# jbr_MDR1986VE3 register map
Registers are 32-bit, access not given, no defined reset value unless marked. A register's access mark holds for its fields unless they carry their own. Addresses are absolute; registers are grouped by the start of their names; [hi:lo] are bit positions; {n}, {i} and the like mark numbered series; 'fields as' and 'values as' point back to an identical list.

## ETH1
0x30000000 ETH1_Dilimiter 16-bit
0x30000002 ETH1_MAC_T 16-bit
0x30000004 ETH1_MAC_M 16-bit
0x30000006 ETH1_MAC_H 16-bit
{0x30000008+2i} ETH1_HASH{i} 16-bit (i=0..3)
0x30000010 ETH1_IPG 16-bit
0x30000012 ETH1_PSC 16-bit
0x30000014 ETH1_BAG 16-bit
0x30000016 ETH1_JitterWnd 16-bit
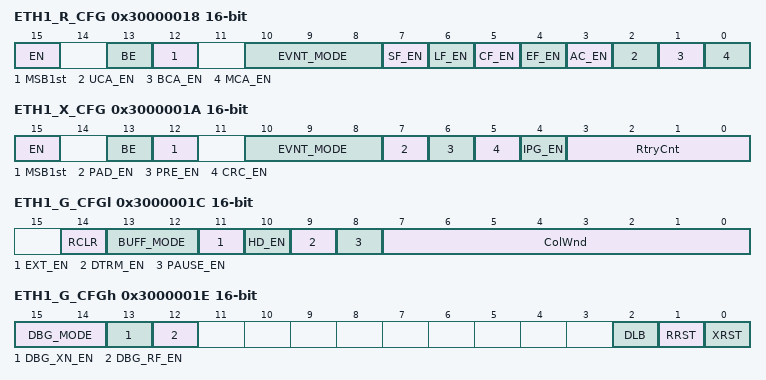
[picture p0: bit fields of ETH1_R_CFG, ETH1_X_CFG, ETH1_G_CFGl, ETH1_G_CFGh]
0x30000018 ETH1_R_CFG 16-bit
  [15] EN, [13] BE, [12] MSB1st, [10:8] EVNT_MODE, [7] SF_EN, [6] LF_EN, [5] CF_EN, [4] EF_EN, [3] AC_EN, [2] UCA_EN, [1] BCA_EN, [0] MCA_EN
0x3000001A ETH1_X_CFG 16-bit
  [15] EN, [13] BE, [12] MSB1st, [10:8] EVNT_MODE, [7] PAD_EN, [6] PRE_EN, [5] CRC_EN, [4] IPG_EN, [3:0] RtryCnt
0x3000001C ETH1_G_CFGl 16-bit
  [14] RCLR, [13:12] BUFF_MODE, [11] EXT_EN, [10] HD_EN, [9] DTRM_EN, [8] PAUSE_EN, [7:0] ColWnd
0x3000001E ETH1_G_CFGh 16-bit
  [15:14] DBG_MODE, [13] DBG_XN_EN, [12] DBG_RF_EN, [2] DLB, [1] RRST, [0] XRST
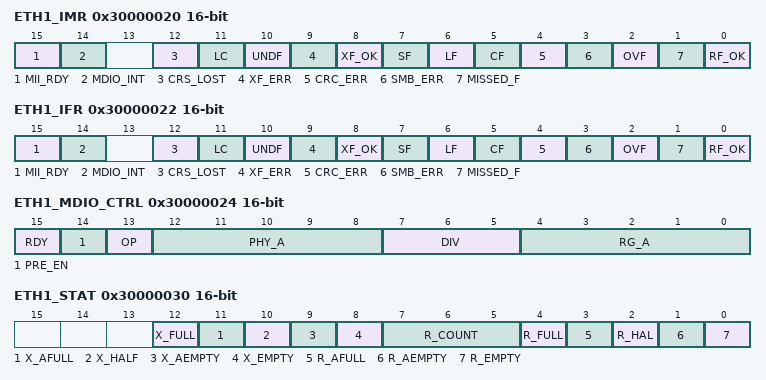
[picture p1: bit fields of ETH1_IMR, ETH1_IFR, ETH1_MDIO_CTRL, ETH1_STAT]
0x30000020 ETH1_IMR 16-bit
  [15] MII_RDY, [14] MDIO_INT, [12] CRS_LOST, [11] LC, [10] UNDF, [9] XF_ERR, [8] XF_OK, [7] SF, [6] LF, [5] CF, [4] CRC_ERR, [3] SMB_ERR, [2] OVF, [1] MISSED_F, [0] RF_OK
0x30000022 ETH1_IFR 16-bit
  fields as ETH1_IMR
0x30000024 ETH1_MDIO_CTRL 16-bit
  [15] RDY, [14] PRE_EN, [13] OP, [12:8] PHY_A, [7:5] DIV, [4:0] RG_A
0x30000026 ETH1_MDIO_DATA 16-bit
0x30000028 ETH1_R_Head 16-bit
0x3000002A ETH1_X_Tail 16-bit
0x3000002C ETH1_R_Tail 16-bit
0x3000002E ETH1_X_Head 16-bit
0x30000030 ETH1_STAT 16-bit
  [12] X_FULL, [11] X_AFULL, [10] X_HALF, [9] X_AEMPTY, [8] X_EMPTY, [7:5] R_COUNT, [4] R_FULL, [3] R_AFULL, [2] R_HAL, [1] R_AEMPTY, [0] R_EMPTY

## PHY1
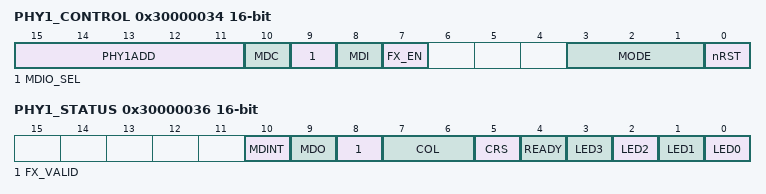
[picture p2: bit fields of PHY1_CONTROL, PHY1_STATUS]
0x30000034 PHY1_CONTROL 16-bit
  [15:11] PHY1ADD, [10] MDC, [9] MDIO_SEL, [8] MDI, [7] FX_EN, [3:1] MODE, [0] nRST
0x30000036 PHY1_STATUS 16-bit
  [10] MDINT, [9] MDO, [8] FX_VALID, [7:6] COL, [5] CRS, [4] READY, [n] LED{n} (n=0..3)

## ETH2
0x34000000 ETH2_Dilimiter 16-bit
0x34000002 ETH2_MAC_T 16-bit
0x34000004 ETH2_MAC_M 16-bit
0x34000006 ETH2_MAC_H 16-bit
{0x34000008+2i} ETH2_HASH{i} 16-bit (i=0..3)
0x34000010 ETH2_IPG 16-bit
0x34000012 ETH2_PSC 16-bit
0x34000014 ETH2_BAG 16-bit
0x34000016 ETH2_JitterWnd 16-bit
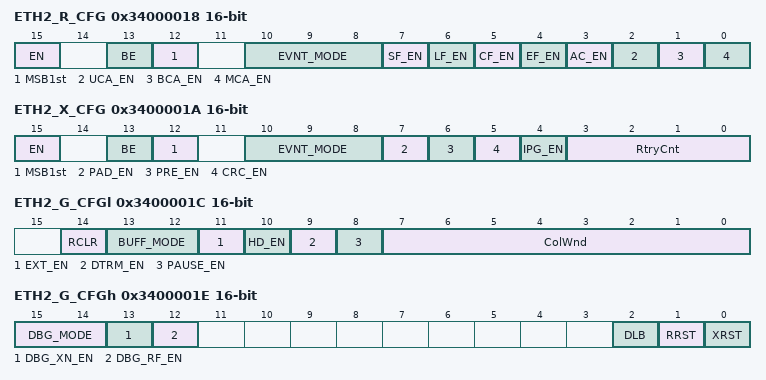
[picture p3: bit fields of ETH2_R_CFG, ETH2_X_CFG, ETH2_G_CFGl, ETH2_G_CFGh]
0x34000018 ETH2_R_CFG 16-bit
  [15] EN, [13] BE, [12] MSB1st, [10:8] EVNT_MODE, [7] SF_EN, [6] LF_EN, [5] CF_EN, [4] EF_EN, [3] AC_EN, [2] UCA_EN, [1] BCA_EN, [0] MCA_EN
0x3400001A ETH2_X_CFG 16-bit
  [15] EN, [13] BE, [12] MSB1st, [10:8] EVNT_MODE, [7] PAD_EN, [6] PRE_EN, [5] CRC_EN, [4] IPG_EN, [3:0] RtryCnt
0x3400001C ETH2_G_CFGl 16-bit
  [14] RCLR, [13:12] BUFF_MODE, [11] EXT_EN, [10] HD_EN, [9] DTRM_EN, [8] PAUSE_EN, [7:0] ColWnd
0x3400001E ETH2_G_CFGh 16-bit
  [15:14] DBG_MODE, [13] DBG_XN_EN, [12] DBG_RF_EN, [2] DLB, [1] RRST, [0] XRST
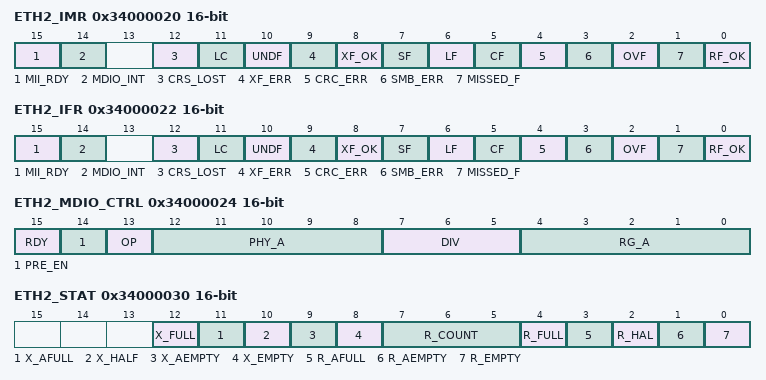
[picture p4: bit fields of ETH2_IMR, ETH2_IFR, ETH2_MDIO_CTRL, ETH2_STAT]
0x34000020 ETH2_IMR 16-bit
  [15] MII_RDY, [14] MDIO_INT, [12] CRS_LOST, [11] LC, [10] UNDF, [9] XF_ERR, [8] XF_OK, [7] SF, [6] LF, [5] CF, [4] CRC_ERR, [3] SMB_ERR, [2] OVF, [1] MISSED_F, [0] RF_OK
0x34000022 ETH2_IFR 16-bit
  fields as ETH2_IMR
0x34000024 ETH2_MDIO_CTRL 16-bit
  [15] RDY, [14] PRE_EN, [13] OP, [12:8] PHY_A, [7:5] DIV, [4:0] RG_A
0x34000026 ETH2_MDIO_DATA 16-bit
0x34000028 ETH2_R_Head 16-bit
0x3400002A ETH2_X_Tail 16-bit
0x3400002C ETH2_R_Tail 16-bit
0x3400002E ETH2_X_Head 16-bit
0x34000030 ETH2_STAT 16-bit
  [12] X_FULL, [11] X_AFULL, [10] X_HALF, [9] X_AEMPTY, [8] X_EMPTY, [7:5] R_COUNT, [4] R_FULL, [3] R_AFULL, [2] R_HAL, [1] R_AEMPTY, [0] R_EMPTY

## PHY2
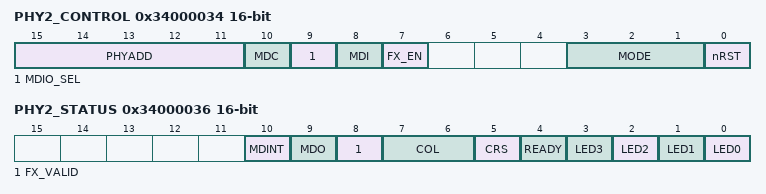
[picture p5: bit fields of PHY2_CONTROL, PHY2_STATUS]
0x34000034 PHY2_CONTROL 16-bit
  [15:11] PHYADD, [10] MDC, [9] MDIO_SEL, [8] MDI, [7] FX_EN, [3:1] MODE, [0] nRST
0x34000036 PHY2_STATUS 16-bit
  [10] MDINT, [9] MDO, [8] FX_VALID, [7:6] COL, [5] CRS, [4] READY, [n] LED{n} (n=0..3)

## SFR
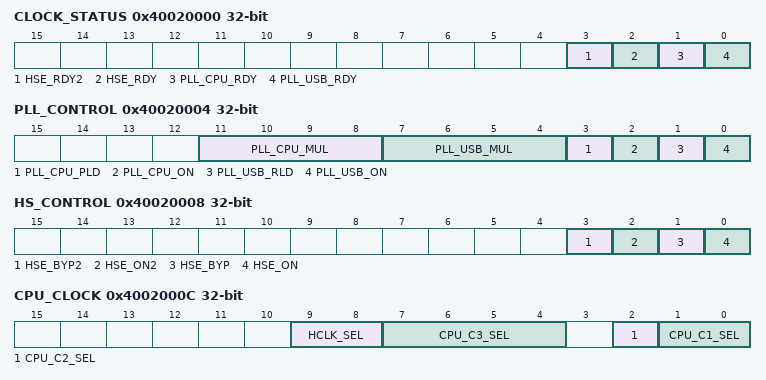
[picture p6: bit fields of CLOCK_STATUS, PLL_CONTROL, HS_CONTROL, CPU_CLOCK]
0x40020000 CLOCK_STATUS
  [3] HSE_RDY2, [2] HSE_RDY, [1] PLL_CPU_RDY, [0] PLL_USB_RDY
0x40020004 PLL_CONTROL
  [11:8] PLL_CPU_MUL, [7:4] PLL_USB_MUL, [3] PLL_CPU_PLD, [2] PLL_CPU_ON, [1] PLL_USB_RLD, [0] PLL_USB_ON
0x40020008 HS_CONTROL
  [3] HSE_BYP2, [2] HSE_ON2, [1] HSE_BYP, [0] HSE_ON
0x4002000C CPU_CLOCK
  [9:8] HCLK_SEL, [7:4] CPU_C3_SEL, [2] CPU_C2_SEL, [1:0] CPU_C1_SEL
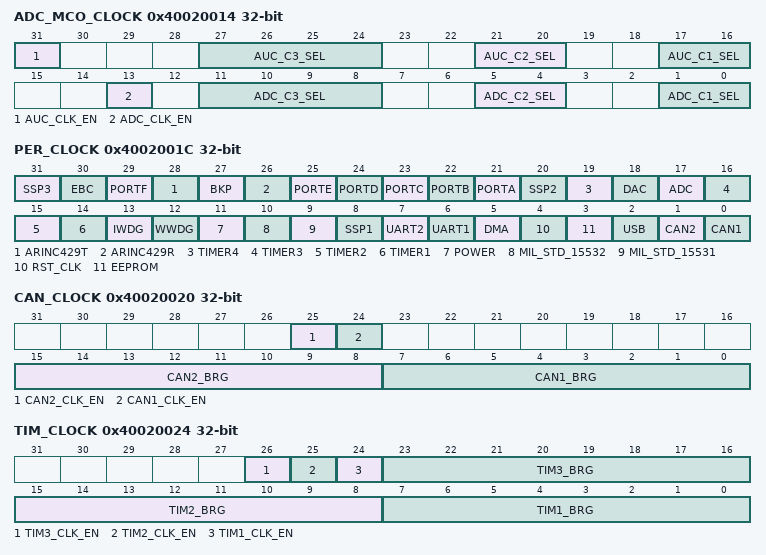
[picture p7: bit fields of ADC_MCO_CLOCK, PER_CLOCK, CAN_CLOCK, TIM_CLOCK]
0x40020014 ADC_MCO_CLOCK
  [31] AUC_CLK_EN, [27:24] AUC_C3_SEL, [21:20] AUC_C2_SEL, [17:16] AUC_C1_SEL, [13] ADC_CLK_EN, [11:8] ADC_C3_SEL, [5:4] ADC_C2_SEL, [1:0] ADC_C1_SEL
0x4002001C PER_CLOCK
  [31] SSP3, [30] EBC, [29] PORTF, [28] ARINC429T, [27] BKP, [26] ARINC429R, [25] PORTE, [24] PORTD, [23] PORTC, [22] PORTB, [21] PORTA, [20] SSP2, [19] TIMER4, [18] DAC, [17] ADC, [16] TIMER3, [15] TIMER2, [14] TIMER1, [13] IWDG, [12] WWDG, [11] POWER, [10] MIL_STD_15532, [9] MIL_STD_15531, [8] SSP1, [7] UART2, [6] UART1, [5] DMA, [4] RST_CLK, [3] EEPROM, [2] USB, [1] CAN2, [0] CAN1
0x40020020 CAN_CLOCK
  [25] CAN2_CLK_EN, [24] CAN1_CLK_EN, [15:8] CAN2_BRG, [7:0] CAN1_BRG
0x40020024 TIM_CLOCK
  [26] TIM3_CLK_EN, [25] TIM2_CLK_EN, [24] TIM1_CLK_EN, [23:16] TIM3_BRG, [15:8] TIM2_BRG, [7:0] TIM1_BRG
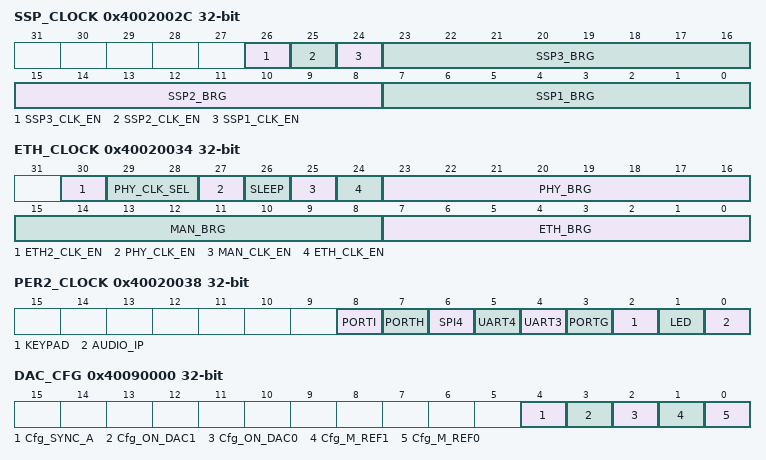
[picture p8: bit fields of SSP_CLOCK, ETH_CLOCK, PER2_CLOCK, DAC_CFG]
0x4002002C SSP_CLOCK
  [26] SSP3_CLK_EN, [25] SSP2_CLK_EN, [24] SSP1_CLK_EN, [23:16] SSP3_BRG, [15:8] SSP2_BRG, [7:0] SSP1_BRG
0x40020034 ETH_CLOCK
  [30] ETH2_CLK_EN, [29:28] PHY_CLK_SEL, [27] PHY_CLK_EN, [26] SLEEP, [25] MAN_CLK_EN, [24] ETH_CLK_EN, [23:16] PHY_BRG, [15:8] MAN_BRG, [7:0] ETH_BRG
0x40020038 PER2_CLOCK
  [8] PORTI, [7] PORTH, [6] SPI4, [5] UART4, [4] UART3, [3] PORTG, [2] KEYPAD, [1] LED, [0] AUDIO_IP
0x40028008 CTRL_BASE_PTR
  [31:10] CTRL_BASE_PTR
0x4002800C ALT_CTRL_BASE_PTR
0x4002804C ERR_CLR
  [0] ERR_CLR
0x40088004 ADC2_CFG
  [17] ADC1_OP
0x40090000 DAC_CFG
  [4] Cfg_SYNC_A, [3] Cfg_ON_DAC1, [2] Cfg_ON_DAC0, [1] Cfg_M_REF1, [0] Cfg_M_REF0
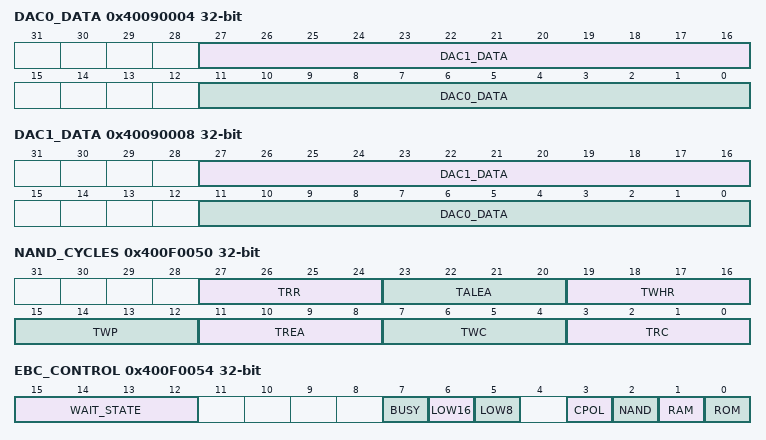
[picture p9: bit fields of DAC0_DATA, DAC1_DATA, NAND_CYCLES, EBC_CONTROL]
0x40090004 DAC0_DATA
  [27:16] DAC1_DATA, [11:0] DAC0_DATA
0x40090008 DAC1_DATA
  [27:16] DAC1_DATA, [11:0] DAC0_DATA
0x400F0050 NAND_CYCLES
  [27:24] TRR, [23:20] TALEA, [19:16] TWHR, [15:12] TWP, [11:8] TREA, [7:4] TWC, [3:0] TRC
0x400F0054 EBC_CONTROL
  [15:12] WAIT_STATE, [7] BUSY, [6] LOW16, [5] LOW8, [3] CPOL, [2] NAND, [1] RAM, [0] ROM
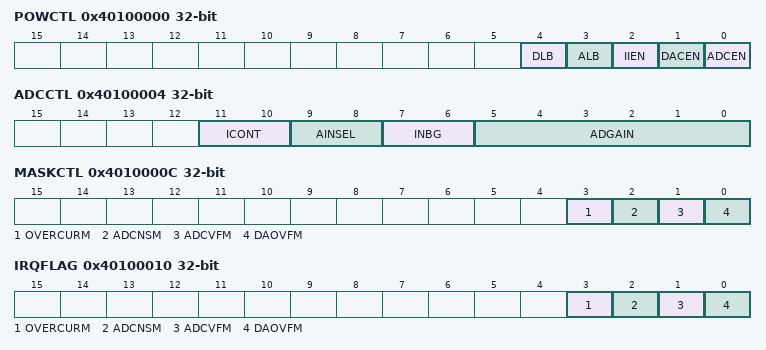
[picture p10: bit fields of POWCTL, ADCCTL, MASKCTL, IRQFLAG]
0x40100000 POWCTL
  [4] DLB, [3] ALB, [2] IIEN, [1] DACEN, [0] ADCEN
0x40100004 ADCCTL
  [11:10] ICONT, [9:8] AINSEL, [7:6] INBG, [5:0] ADGAIN
0x40100008 DACCTL
  [15] DACRES, [11] OVECBS, [10] OVECBA, [9] ODDAC, [8] BIAS, [7] ODAMP, [6] MUTE1, [6] SIDETONE, [5:0] DAGAIN
0x4010000C MASKCTL
  [3] OVERCURM, [2] ADCNSM, [1] ADCVFM, [0] DAOVFM
0x40100010 IRQFLAG
  [3] OVERCURM, [2] ADCNSM, [1] ADCVFM, [0] DAOVFM
0x40100014 ADCREG
  [15:0] ADCSMP
0x40100018 DACREG
  [15:0] DACSMPMsk
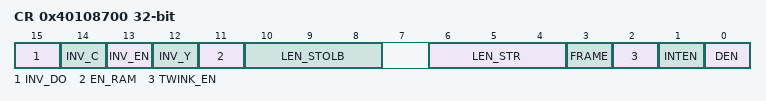
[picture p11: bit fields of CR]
0x40108700 CR
  [15] INV_DO, [14] INV_C, [13] INV_EN, [12] INV_Y, [11] EN_RAM, [10:8] LEN_STOLB, [6:4] LEN_STR, [3] FRAME, [2] TWINK_EN, [1] INTEN, [0] DEN
0x40108E04 Jark
0x40109510 DivR
0x40109C1C SR
  [0] WR_REDY

## KEYPAD
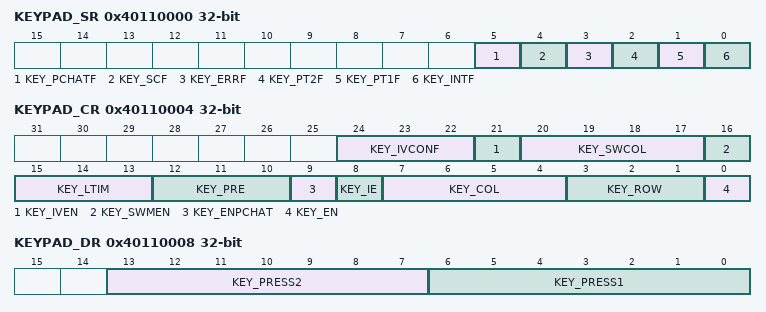
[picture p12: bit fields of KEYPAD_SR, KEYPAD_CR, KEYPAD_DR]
0x40110000 KEYPAD_SR
  [5] KEY_PCHATF, [4] KEY_SCF, [3] KEY_ERRF, [2] KEY_PT2F, [1] KEY_PT1F, [0] KEY_INTF
0x40110004 KEYPAD_CR
  [24:22] KEY_IVCONF, [21] KEY_IVEN, [20:17] KEY_SWCOL, [16] KEY_SWMEN, [15:13] KEY_LTIM, [12:10] KEY_PRE, [9] KEY_ENPCHAT, [8] KEY_IE, [7:4] KEY_COL, [3:1] KEY_ROW, [0] KEY_EN
0x40110008 KEYPAD_DR
  [13:7] KEY_PRESS2, [6:0] KEY_PRESS1
